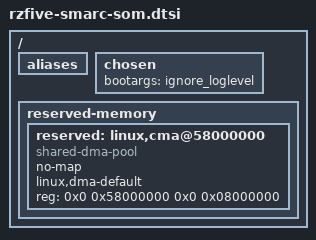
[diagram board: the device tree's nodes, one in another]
// SPDX-License-Identifier: (GPL-2.0-only OR BSD-2-Clause)
/*
 * Device Tree Source for the RZ/Five SMARC EVK SOM
 *
 * Copyright (C) 2022 Renesas Electronics Corp.
 */

#include <arm64/renesas/rzg2ul-smarc-som.dtsi>

/ {
	aliases {
		/delete-property/ ethernet0;
		/delete-property/ ethernet1;
	};

	chosen {
		bootargs = "ignore_loglevel";
	};

	reserved-memory {
		#address-cells = <2>;
		#size-cells = <2>;
		ranges;

		reserved: linux,cma@58000000 {
			compatible = "shared-dma-pool";
			no-map;
			linux,dma-default;
			reg = <0x0 0x58000000 0x0 0x08000000>;
		};
	};
};
